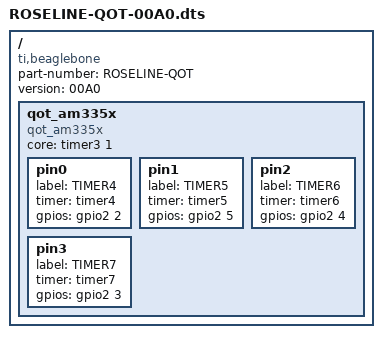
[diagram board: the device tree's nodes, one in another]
/dts-v1/;
/plugin/;
 
/ {
    /* what boards are we compatible with */
    compatible = "ti,beaglebone", "ti,beaglebone-black";
 
    /* identification */
    part-number = "ROSELINE-QOT";
 
    /* special version ignores EEPROM */
    version = "00A0";

    /* Setup the am335x timer subsystem as a PHC */
    fragment@1 {
        target-path="/";
        __overlay__ {
            qot_am335x {
                compatible = "qot_am335x";
                status = "okay";
                core  = <&timer3 1>; /* 0 = SYS, 1 = RTC, 2 = TCLKIN */
                pin0 {
                    label = "TIMER4";
                    timer = <&timer4>;
                    gpios = <&gpio2 2 0>;
                };
                pin1 {
                    label = "TIMER5";
                    timer = <&timer5>;
                    gpios = <&gpio2 5 0>;
                };
                pin2 {
                    label = "TIMER6";
                    timer = <&timer6>;
                    gpios = <&gpio2 4 0>;
                };
                pin3 {
                    label = "TIMER7";
                    timer = <&timer7>;
                    gpios = <&gpio2 3 0>;
                };
            };
        };
    };
};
